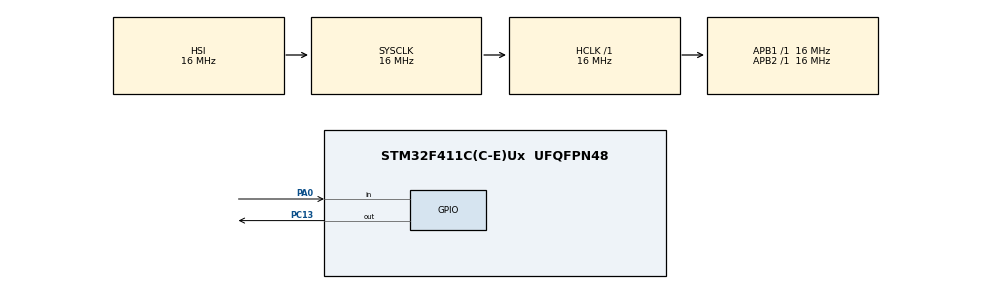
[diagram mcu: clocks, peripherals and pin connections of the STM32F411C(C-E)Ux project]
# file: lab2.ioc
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Mcu.Family=STM32F4
RCC.CortexFreq_Value=16000000
ProjectManager.StackSize=0x400
PA0-WKUP.Signal=GPIO_Input
PA13.Signal=SYS_JTMS-SWDIO
PH0\ -\ OSC_IN.Signal=RCC_OSC_IN
ProjectManager.TargetToolchain=STM32CubeIDE
RCC.LSE_VALUE=32768
RCC.AHBFreq_Value=16000000
RCC.HSE_VALUE=25000000
PH1\ -\ OSC_OUT.Signal=RCC_OSC_OUT
board=custom
PC13-ANTI_TAMP.Signal=GPIO_Output
RCC.VCOOutputFreq_Value=192000000
RCC.APB2Freq_Value=16000000
Mcu.Name=STM32F411C(C-E)Ux
RCC.SYSCLKFreq_VALUE=16000000
Mcu.Package=UFQFPN48
PA14.Signal=SYS_JTCK-SWCLK
ProjectManager.HeapSize=0x200
RCC.HSI_VALUE=16000000
NVIC.PriorityGroup=NVIC_PRIORITYGROUP_4
RCC.APB1Freq_Value=16000000

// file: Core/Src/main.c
/* USER CODE BEGIN Header */
/**
  ******************************************************************************
  * @file           : main.c
  * @brief          : Main program body
  ******************************************************************************
  * @attention
  *
  * <h2><center>&copy; Copyright (c) 2021 STMicroelectronics.
  * All rights reserved.</center></h2>
  *
  * This software component is licensed by ST under BSD 3-Clause license,
  * the "License"; You may not use this file except in compliance with the
  * License. You may obtain a copy of the License at:
  *                        opensource.org/licenses/BSD-3-Clause
  *
  ******************************************************************************
  */
/* USER CODE END Header */
#include "main.h"

/* USER CODE BEGIN PD */

#define LED_ON GPIOC -> BSRR = GPIO_PIN_13
#define LED_OFF GPIOC -> BSRR = (GPIO_PIN_13 << 16)
#define BTN_KEY GPIOA -> IDR & GPIO_PIN_0

/* USER CODE END PD */

void SystemClock_Config(void);
static void MX_GPIO_Init(void);

int main(void)
{

  /* MCU Configuration--------------------------------------------------------*/

  /* Reset of all peripherals, Initializes the Flash interface and the Systick. */
  HAL_Init();

  /* Configure the system clock */
  SystemClock_Config();

  /* Initialize all configured peripherals */
  MX_GPIO_Init();

  /* Infinite loop */
  /* USER CODE BEGIN WHILE */
  while (1)
  {
	  if (BTN_KEY && htim->Instance == TIM1){
	  		LED_ON;
	  	} else{
	  		LED_OFF;
	  	}
	  /* USER CODE END WHILE */

  }
}

void SystemClock_Config(void)
{
  RCC_OscInitTypeDef RCC_OscInitStruct = {0};
  RCC_ClkInitTypeDef RCC_ClkInitStruct = {0};

  /** Configure the main internal regulator output voltage
  */
  __HAL_RCC_PWR_CLK_ENABLE();
  __HAL_PWR_VOLTAGESCALING_CONFIG(PWR_REGULATOR_VOLTAGE_SCALE1);
  /** Initializes the RCC Oscillators according to the specified parameters
  * in the RCC_OscInitTypeDef structure.
  */
  RCC_OscInitStruct.OscillatorType = RCC_OSCILLATORTYPE_HSI;
  RCC_OscInitStruct.HSIState = RCC_HSI_ON;
  RCC_OscInitStruct.HSICalibrationValue = RCC_HSICALIBRATION_DEFAULT;
  RCC_OscInitStruct.PLL.PLLState = RCC_PLL_NONE;
  if (HAL_RCC_OscConfig(&RCC_OscInitStruct) != HAL_OK)
  {
    Error_Handler();
  }
  /** Initializes the CPU, AHB and APB buses clocks
  */
  RCC_ClkInitStruct.ClockType = RCC_CLOCKTYPE_HCLK|RCC_CLOCKTYPE_SYSCLK
                              |RCC_CLOCKTYPE_PCLK1|RCC_CLOCKTYPE_PCLK2;
  RCC_ClkInitStruct.SYSCLKSource = RCC_SYSCLKSOURCE_HSI;
  RCC_ClkInitStruct.AHBCLKDivider = RCC_SYSCLK_DIV1;
  RCC_ClkInitStruct.APB1CLKDivider = RCC_HCLK_DIV1;
  RCC_ClkInitStruct.APB2CLKDivider = RCC_HCLK_DIV1;

  if (HAL_RCC_ClockConfig(&RCC_ClkInitStruct, FLASH_LATENCY_0) != HAL_OK)
  {
    Error_Handler();
  }
}

static void MX_GPIO_Init(void)
{
  GPIO_InitTypeDef GPIO_InitStruct = {0};

  /* GPIO Ports Clock Enable */
  __HAL_RCC_GPIOC_CLK_ENABLE();
  __HAL_RCC_GPIOH_CLK_ENABLE();
  __HAL_RCC_GPIOA_CLK_ENABLE();

  /*Configure GPIO pin Output Level */
  HAL_GPIO_WritePin(GPIOC, GPIO_PIN_13, GPIO_PIN_RESET);

  /*Configure GPIO pin : PC13 */
  GPIO_InitStruct.Pin = GPIO_PIN_13;
  GPIO_InitStruct.Mode = GPIO_MODE_OUTPUT_PP;
  GPIO_InitStruct.Pull = GPIO_NOPULL;
  GPIO_InitStruct.Speed = GPIO_SPEED_FREQ_LOW;
  HAL_GPIO_Init(GPIOC, &GPIO_InitStruct);

  /*Configure GPIO pin : PA0 */
  GPIO_InitStruct.Pin = GPIO_PIN_0;
  GPIO_InitStruct.Mode = GPIO_MODE_INPUT;
  GPIO_InitStruct.Pull = GPIO_NOPULL;
  HAL_GPIO_Init(GPIOA, &GPIO_InitStruct);

}

void Error_Handler(void)
{
  __disable_irq();
  while (1)
  {
  }
}

/************************ (C) COPYRIGHT STMicroelectronics *****END OF FILE****/
